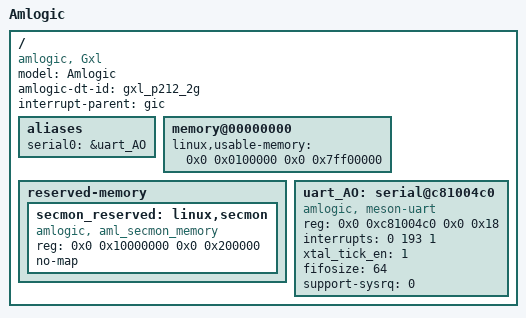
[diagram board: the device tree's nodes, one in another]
/*
 * arch/arm64/boot/dts/amlogic/gxl_p212_2g.dts
 *
 * Copyright (C) 2017 Amlogic, Inc. All rights reserved.
 *
 * This program is free software; you can redistribute it and/or modify
 * it under the terms of the GNU General Public License as published by
 * the Free Software Foundation; either version 2 of the License, or
 * (at your option) any later version.
 *
 * This program is distributed in the hope that it will be useful, but WITHOUT
 * ANY WARRANTY; without even the implied warranty of MERCHANTABILITY or
 * FITNESS FOR A PARTICULAR PURPOSE.  See the GNU General Public License for
 * more details.
 *
 */

/dts-v1/;

#include <dt-bindings/interrupt-controller/arm-gic.h>
#include "mesongxl.dtsi"
/ {
	model = "Amlogic";
	amlogic-dt-id = "gxl_p212_2g";
	compatible = "amlogic, Gxl";
	interrupt-parent = <&gic>;
	#address-cells = <2>;
	#size-cells = <2>;

	aliases {
		serial0 = &uart_AO;
	};

	memory@00000000 {
		device_type = "memory";
		linux,usable-memory = <0x0 0x0100000 0x0 0x7ff00000>;
	};

	reserved-memory {
		#address-cells = <2>;
		#size-cells = <2>;
		ranges;
		/* global autoconfigured region for contiguous allocations */
		secmon_reserved:linux,secmon {
			compatible = "amlogic, aml_secmon_memory";
			reg = <0x0 0x10000000 0x0 0x200000>;
			no-map;
		};
	};

	uart_AO: serial@c81004c0 {
		compatible = "amlogic, meson-uart";
		reg = <0x0 0xc81004c0 0x0 0x18>;
		interrupts = <0 193 1>;
		status = "okay";
		xtal_tick_en = <1>;
		fifosize = < 64 >;
		support-sysrq = <0>;	/* 0 not support , 1 support */
	};
};
